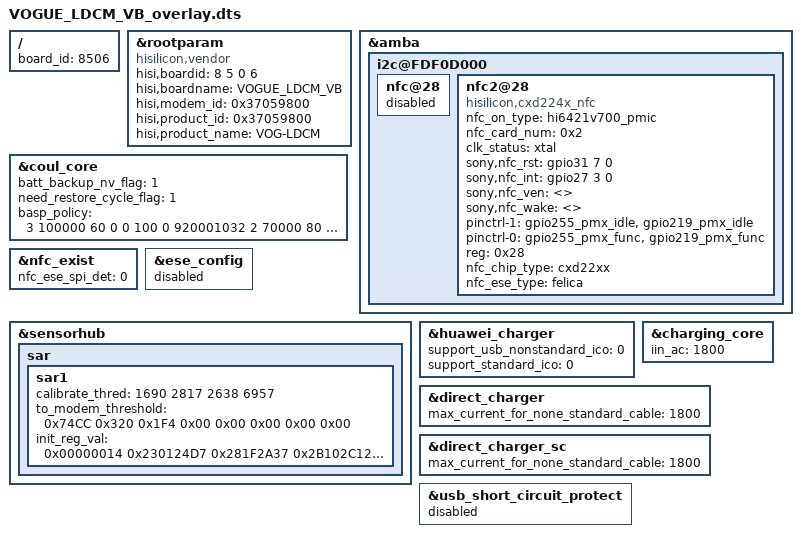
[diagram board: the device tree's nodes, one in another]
/**
 * Copyright (C) 2014 Hisilicon Ltd.
 *
 *  This program is free software; you can redistribute it and/or modify
 *  it under the terms of the GNU General Public License version 2 as
 *  publishhed by the Free Software Foundation.
 */

/dts-v1/;
/plugin/;
/include/ "VOGUE_LX4_VB_overlay.dtsi"
/include/ "VOGUE_LDCM_VB_pin.dtsi"
/include/ "VOGUE_LDCM_VB_modem_pin.dtsi"

/ {
    board_id = <8506>;
};
    &rootparam{
		compatible = "hisilicon,vendor";
		hisi,boardid = <8 5 0 6>;
		hisi,boardname = "VOGUE_LDCM_VB";
		hisi,modem_id = <0x37059800>;
		hisi,product_id = <0x37059800>;
		hisi,product_name = "VOG-LDCM";
	};
	&amba {
		i2c@FDF0D000 {
				nfc@28{
						status = "disabled";
				};
				nfc2@28{
						status = "ok";
						compatible = "hisilicon,cxd224x_nfc";
						nfc_on_type = "hi6421v700_pmic";
						nfc_card_num = <0x2>;
						clk_status = "xtal";
						sony,nfc_rst = <&gpio31 7 0>;
						sony,nfc_int = <&gpio27 3 0>;
						sony,nfc_ven = <>;
						sony,nfc_wake = <>;
						pinctrl-1 = <&gpio255_pmx_idle &gpio219_pmx_idle>;
						pinctrl-0 = <&gpio255_pmx_func &gpio219_pmx_func>;
						pinctrl-names = "default","idle";
						reg = <0x28>;
						nfc_chip_type = "cxd22xx";
						nfc_ese_type = "felica";
				};
		};
    };

    &coul_core {
        batt_backup_nv_flag = <1>;
        need_restore_cycle_flag = <1>;
        status = "ok";
    };

	&nfc_exist {
		nfc_ese_spi_det = "0";
	};

	&ese_config {
		status = "disabled";
	};

	&sensorhub{
		sar{
			sar1{
				calibrate_thred = /bits/ 16 <1690 2817 2638 6957>;//for the factory far and near calibrate
				to_modem_threshold = /bits/ 16 <0x74CC 0x320 0x1F4 0x00 0x00 0x00 0x00 0x00>;
				init_reg_val = <0x00000014 0x230124D7 0x281F2A37 0x2B102C12 0x2D0B3023 0x340B3500 0x361a3708 0x10164219 0x43394430 0x293D2600 0x27472000 0x00000000>;
			};
		};
	};

	&coul_core {
		basp_policy = <
			3 100000 60  0  0  100  0 920001032
			2 70000 80  0  0  100  0 920001031
			1 40000 90  0  0  100  0 920001029
			0 0     0   0  0  100  0 0
		>;
	};

	&huawei_charger {
		support_usb_nonstandard_ico = <0>;
		support_standard_ico = <0>;
	};

	&charging_core {
		iin_ac = <1800>;
	};

	&direct_charger {
		max_current_for_none_standard_cable = <1800>;
	};

	&direct_charger_sc {
		max_current_for_none_standard_cable = <1800>;
	};

	&usb_short_circuit_protect {
		status = "disabled";
	};

